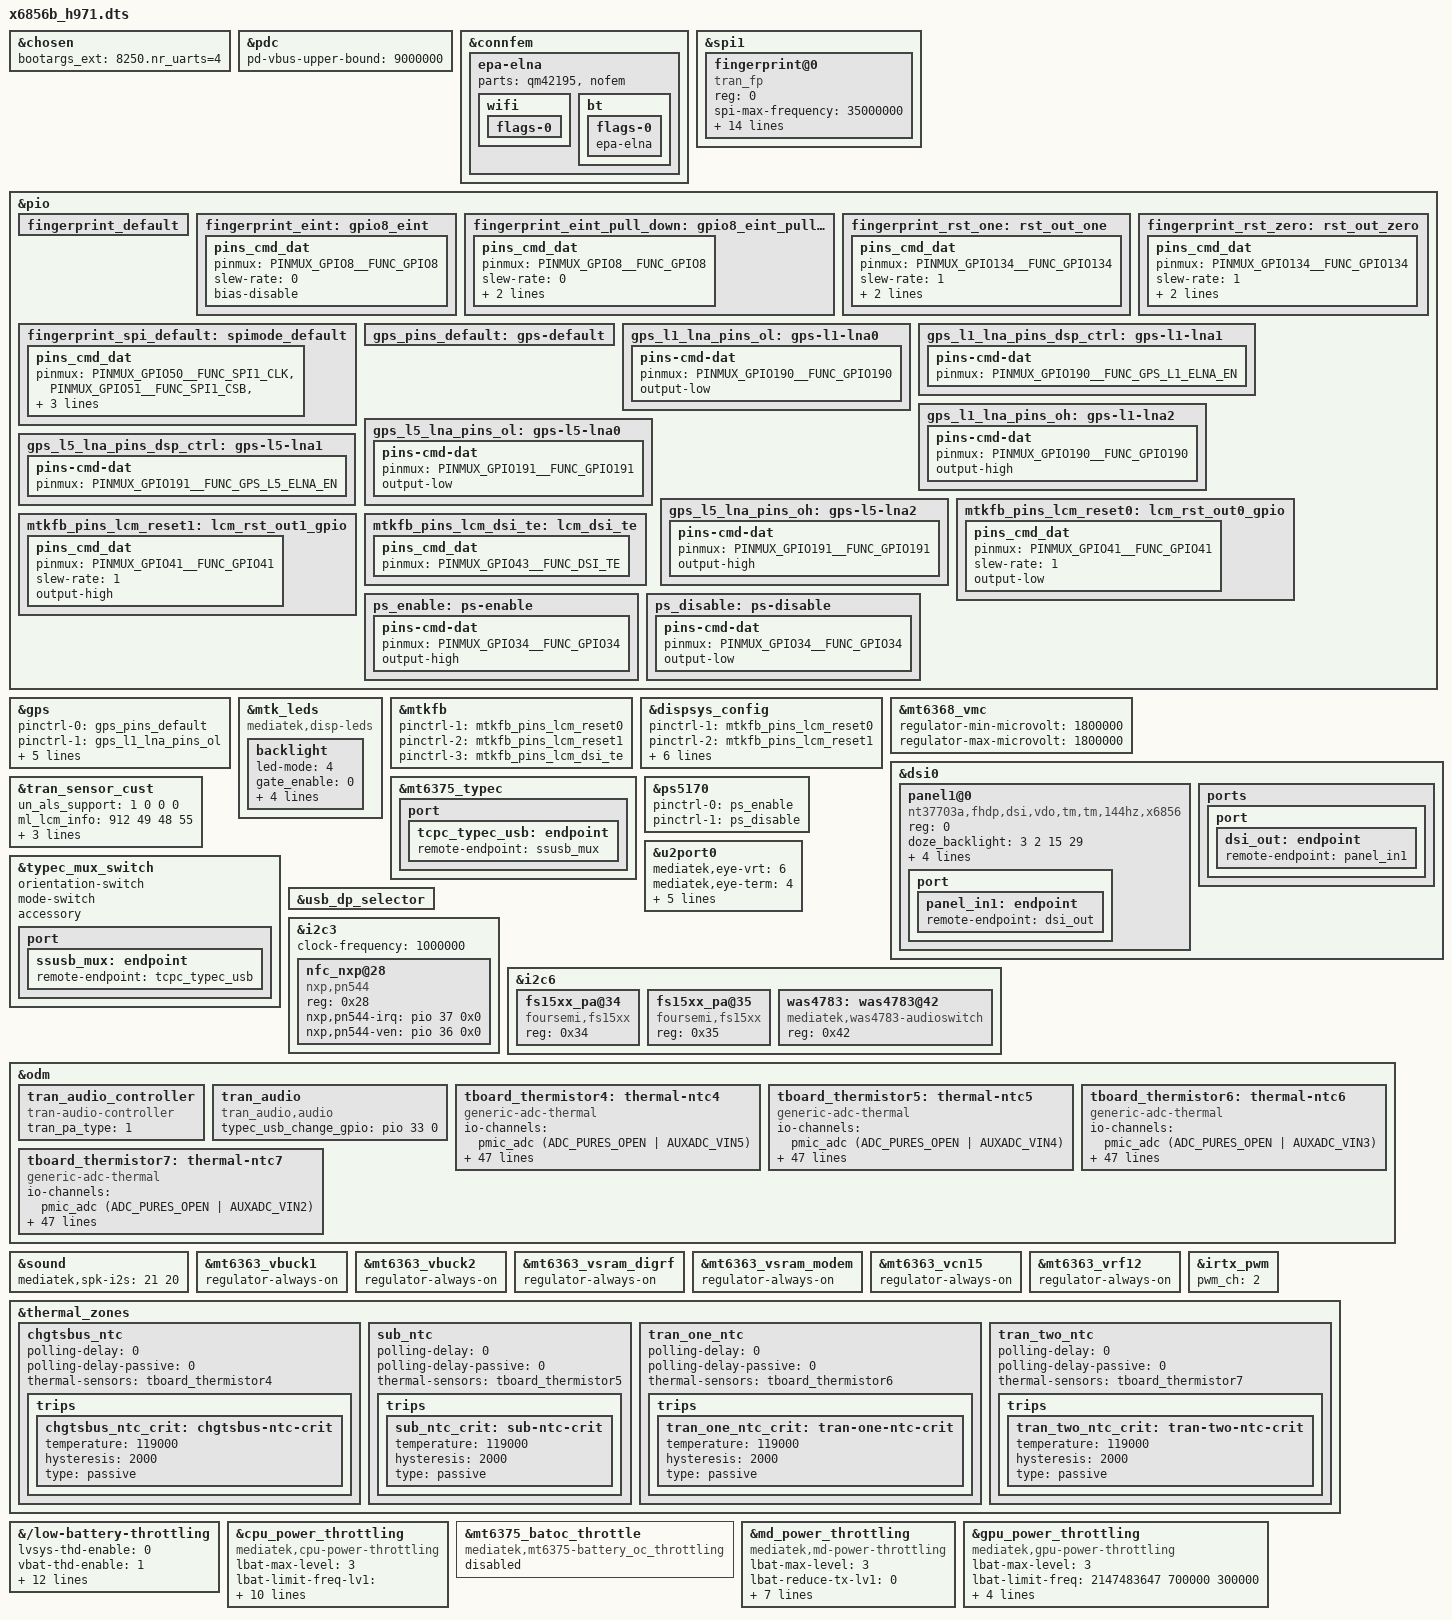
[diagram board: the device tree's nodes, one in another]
// SPDX-License-Identifier: (GPL-2.0 OR MIT)
/*
 * Copyright (C) 2022 MediaTek Inc.
 */
/dts-v1/;
/plugin/;
#include <dt-bindings/interrupt-controller/arm-gic.h>
#include <dt-bindings/interrupt-controller/irq.h>
#include <dt-bindings/pinctrl/mt6897-pinfunc.h>
#include <dt-bindings/phy/phy.h>
#include <dt-bindings/iio/mt635x-auxadc.h>
&chosen {
bootargs_ext = "8250.nr_uarts=4";
};

&pdc {
	pd-vbus-upper-bound = <9000000>;
};

&connfem {
/* Enable epa_elna node to support Wifi & BT ePA/eLNA FEM on customer load */
#if 1
	epa-elna {
		parts = <&qm42195 &nofem>;	/* [0] */
		wifi {
			flags-0 {
				/*open-loop;*/
			};
		};
		bt {
			flags-0 {
				/* choose one of: epa-elna/epa/elna/bypass */
				epa-elna;
			};
		};
	};
#endif
};

&spi1 {
	fingerprint@0 {
		compatible = "tran_fp";
		reg = <0>;
		spi-max-frequency = <35000000>;
		interrupt-parent = <&pio>;
		interrupts = <8 1 8 0>;
		debounce = <27 0>;
		irq-gpio = <8>;
		irq-gpio-std = <&pio 8 0x0>;
		reset-gpio = <134>;
		reset-gpio-std = <&pio 134 0x0>;
		vmch-supply = <&mt6368_vfp>;
		pinctrl-names ="tran_fp_default",
			"tran_fp_pin_irq",
			"tran_fp_irq_pull_down",
			"tran_fp_reset_high",
			"tran_fp_reset_low",
			"tran_fp_spi_default";
		pinctrl-0 = <&fingerprint_default>;
		pinctrl-1 = <&fingerprint_eint>;
		pinctrl-2 = <&fingerprint_eint_pull_down>;
		pinctrl-3 = <&fingerprint_rst_one>;
		pinctrl-4 = <&fingerprint_rst_zero>;
		pinctrl-5 = <&fingerprint_spi_default>;
		status = "okay";
	};
};
&pio {
fingerprint_default: fingerprint_default {
					};
fingerprint_eint: gpio8_eint {
					pins_cmd_dat {
						pinmux = <PINMUX_GPIO8__FUNC_GPIO8>;
						slew-rate = <0>;
						bias-disable;
					};
				};
fingerprint_eint_pull_down: gpio8_eint_pull_down {
								pins_cmd_dat {
									pinmux = <PINMUX_GPIO8__FUNC_GPIO8>;
									slew-rate = <0>;
									bias-pull-down = <00>;
									output-low;
								};
							};
fingerprint_rst_one: rst_out_one {
						pins_cmd_dat {
							pinmux = <PINMUX_GPIO134__FUNC_GPIO134>;
							slew-rate = <1>;
							bias-disable;
							output-high;
						};
					};
fingerprint_rst_zero: rst_out_zero {
						pins_cmd_dat {
							pinmux = <PINMUX_GPIO134__FUNC_GPIO134>;
							slew-rate = <1>;
							bias-disable;
							output-low;
						};
					};
fingerprint_spi_default: spimode_default {
							pins_cmd_dat {
								pinmux = <PINMUX_GPIO50__FUNC_SPI1_CLK>,
										<PINMUX_GPIO51__FUNC_SPI1_CSB>,
										<PINMUX_GPIO52__FUNC_SPI1_MI>,
										<PINMUX_GPIO53__FUNC_SPI1_MO>;
								drive-strength = <7>;
							};
						};
};

/* GPS GPIO standardization start */
&pio {
	gps_pins_default: gps-default {
	};
	gps_l1_lna_pins_ol: gps-l1-lna0 {
		pins-cmd-dat {
			pinmux = <PINMUX_GPIO190__FUNC_GPIO190>;
			output-low;
		};
	};
	gps_l1_lna_pins_dsp_ctrl: gps-l1-lna1 {
		pins-cmd-dat {
			pinmux = <PINMUX_GPIO190__FUNC_GPS_L1_ELNA_EN>;
		};
	};
	gps_l1_lna_pins_oh: gps-l1-lna2 {
		pins-cmd-dat {
			pinmux = <PINMUX_GPIO190__FUNC_GPIO190>;
			output-high;
		};
	};
	gps_l5_lna_pins_ol: gps-l5-lna0 {
		pins-cmd-dat {
			pinmux = <PINMUX_GPIO191__FUNC_GPIO191>;
			output-low;
		};
	};
	gps_l5_lna_pins_dsp_ctrl: gps-l5-lna1 {
		pins-cmd-dat {
			pinmux = <PINMUX_GPIO191__FUNC_GPS_L5_ELNA_EN>;
		};
	};
	gps_l5_lna_pins_oh: gps-l5-lna2 {
		pins-cmd-dat {
			pinmux = <PINMUX_GPIO191__FUNC_GPIO191>;
			output-high;
		};
	};
};
&gps {
	pinctrl-names = "default",
		"gps_l1_lna_disable",
		"gps_l1_lna_dsp_ctrl",
		"gps_l1_lna_enable",
		"gps_l5_lna_disable",
		"gps_l5_lna_dsp_ctrl",
		"gps_l5_lna_enable";
	pinctrl-0 = <&gps_pins_default>;
	pinctrl-1 = <&gps_l1_lna_pins_ol>;
	pinctrl-2 = <&gps_l1_lna_pins_dsp_ctrl>;
	pinctrl-3 = <&gps_l1_lna_pins_oh>;
	pinctrl-4 = <&gps_l5_lna_pins_ol>;
	pinctrl-5 = <&gps_l5_lna_pins_dsp_ctrl>;
	pinctrl-6 = <&gps_l5_lna_pins_oh>;
	status = "okay";
};
/* GPS GPIO standardization end */

&mtk_leds {
	compatible = "mediatek,disp-leds";

	backlight {
		led-mode = <4>;
		gate_enable = <0>;
		pwm_config = <0 1 0 0 0>;
		max-brightness = <511>;
		min-brightness = <0>;
		max-hw-brightness = <511>;
	};
};

&pio {
	mtkfb_pins_lcm_reset0: lcm_rst_out0_gpio {
		pins_cmd_dat {
			pinmux = <PINMUX_GPIO41__FUNC_GPIO41>;
			slew-rate = <1>;
			output-low;
		};
	};

	mtkfb_pins_lcm_reset1: lcm_rst_out1_gpio {
		pins_cmd_dat {
			pinmux = <PINMUX_GPIO41__FUNC_GPIO41>;
			slew-rate = <1>;
			output-high;
		};
	};

	mtkfb_pins_lcm_dsi_te: lcm_dsi_te {
		pins_cmd_dat {
			pinmux = <PINMUX_GPIO43__FUNC_DSI_TE>;
		};
	};
};

&mtkfb {
	pinctrl-names = "lcm_rst_out0_gpio", "lcm_rst_out1_gpio",
		"mode_te_te";
	pinctrl-1 = <&mtkfb_pins_lcm_reset0>;
	pinctrl-2 = <&mtkfb_pins_lcm_reset1>;
	pinctrl-3 = <&mtkfb_pins_lcm_dsi_te>;
	status = "okay";
};

&dispsys_config {
	pinctrl-names = "lcm_rst_out0_gpio", "lcm_rst_out1_gpio",
		"mode_te_te";
	pinctrl-1 = <&mtkfb_pins_lcm_reset0>;
	pinctrl-2 = <&mtkfb_pins_lcm_reset1>;
	pinctrl-3 = <&mtkfb_pins_lcm_dsi_te>;
	status = "okay";

	helper-value = <0>, /*MTK_DRM_OPT_STAGE*/
		<1>, /*MTK_DRM_OPT_USE_CMDQ*/
		<1>, /*MTK_DRM_OPT_USE_M4U*/
		<1>, /*MTK_DRM_OPT_MMQOS_SUPPORT*/
		<1>, /*MTK_DRM_OPT_MMDVFS_SUPPORT*/
		<0>, /*MTK_DRM_OPT_SODI_SUPPORT*/
		<1>, /*MTK_DRM_OPT_IDLE_MGR*/
		<0>, /*MTK_DRM_OPT_IDLEMGR_SWTCH_DECOUPLE*/
		<0>, /*MTK_DRM_OPT_IDLEMGR_BY_REPAINT*/
		<0>, /*MTK_DRM_OPT_IDLEMGR_ENTER_ULPS*/
		<0>, /*MTK_DRM_OPT_IDLEMGR_KEEP_LP11*/
		<0>, /*MTK_DRM_OPT_DYNAMIC_RDMA_GOLDEN_SETTING*/
		<1>, /*MTK_DRM_OPT_IDLEMGR_DISABLE_ROUTINE_IRQ*/
		<1>, /*MTK_DRM_OPT_IDLEMGR_ASYNC*/
		<0>, /*MTK_DRM_OPT_MET_LOG*/
		<1>, /*MTK_DRM_OPT_USE_PQ*/
		<1>, /*MTK_DRM_OPT_ESD_CHECK_RECOVERY*/
		<1>, /*MTK_DRM_OPT_ESD_CHECK_SWITCH*/
		<1>, /*MTK_DRM_OPT_PRESENT_FENCE*/
		<0>, /*MTK_DRM_OPT_RDMA_UNDERFLOW_AEE*/
		<1>, /*MTK_DRM_OPT_DSI_UNDERRUN_AEE*/
		<0>, /*MTK_DRM_OPT_ODDMR_OD_AEE*/
		<0>, /*MTK_DRM_OPT_ODDMR_DMR_AEE*/
		<1>, /*MTK_DRM_OPT_HRT*/
		<1>, /*MTK_DRM_OPT_HRT_MODE*/
		<0>, /*MTK_DRM_OPT_DELAYED_TRIGGER*/
		<1>, /*MTK_DRM_OPT_OVL_EXT_LAYER*/
		<1>, /*MTK_DRM_OPT_AOD*/
		<1>, /*MTK_DRM_OPT_RPO*/
		<0>, /*MTK_DRM_OPT_DUAL_PIPE*/
		<0>, /*MTK_DRM_OPT_DC_BY_HRT*/
		<1>, /*MTK_DRM_OPT_OVL_WCG*/
		<0>, /*MTK_DRM_OPT_OVL_SBCH*/
		<1>, /*MTK_DRM_OPT_COMMIT_NO_WAIT_VBLANK*/
		<0>, /*MTK_DRM_OPT_MET*/
		<0>, /*MTK_DRM_OPT_REG_PARSER_RAW_DUMP*/
		<0>, /*MTK_DRM_OPT_VP_PQ*/
		<0>, /*MTK_DRM_OPT_GAME_PQ*/
		<0>, /*MTK_DRM_OPT_MMPATH*/
		<1>, /*MTK_DRM_OPT_HBM*/
		<0>, /*MTK_DRM_OPT_VDS_PATH_SWITCH*/
		<0>, /*MTK_DRM_OPT_LAYER_REC*/
		<1>, /*MTK_DRM_OPT_CLEAR_LAYER*/
		<1>, /*MTK_DRM_OPT_LFR*/
		<0>, /*MTK_DRM_OPT_SF_PF*/
		<1>, /*MTK_DRM_OPT_DYN_MIPI_CHANGE*/
		<1>, /*MTK_DRM_OPT_PRIM_DUAL_PIPE*/
		<1>, /*MTK_DRM_OPT_MSYNC2_0*/
		<1>, /*MTK_DRM_OPT_MML_PRIMARY*/
		<1>, /*MTK_DRM_OPT_MML_SUPPORT_CMD_MODE*/
		<1>, /*MTK_DRM_OPT_MML_PQ*/
		<1>, /*MTK_DRM_OPT_MML_IR*/
		<0>, /*MTK_DRM_OPT_DUAL_TE*/
		<1>, /*MTK_DRM_OPT_RES_SWITCH*/
		<0>, /*MTK_DRM_OPT_PREFETCH_TE*/
		<0>, /*MTK_DRM_OPT_VIDLE_APSRC_OFF*/
		<0>, /*MTK_DRM_OPT_VIDLE_DSI_PLL_OFF*/
		<1>, /*MTK_DRM_OPT_CHECK_TRIGGER_MERGE*/
		<1>, /*MTK_DRM_OPT_VIRTUAL_DISP*/
		<1>, /*MTK_DRM_OPT_OVL_BW_MONITOR*/
		<0>, /*MTK_DRM_OPT_GPU_CACHE*/
		<1>, /*MTK_DRM_OPT_SPHRT*/
		<1>, /*MTK_DRM_OPT_SDPA_OVL_SWITCH*/
		<1>, /*MTK_DRM_OPT_HRT_BY_LARB*/
		<1>, /*MTK_DRM_OPT_RES_SWITCH_ON_AP*/
		<1>, /*MTK_DRM_OPT_TILE_OVERHEAD*/
		<0>; /*MTK_DRM_OPT_VBLANK_CONFIG_REC*/
};

&mt6368_vmc {
	regulator-min-microvolt = <1800000>;
	regulator-max-microvolt = <1800000>;
};

&dsi0 {
	status = "okay";
	#address-cells = <1>;
	#size-cells = <0>;
	panel1@0 {
		compatible = "nt37703a,fhdp,dsi,vdo,tm,tm,144hz,x6856";
		reg = <0>;
		doze_backlight = <3 2 15 29>;
		vddi-supply = <&mt6368_vmc>;
		dvdd-supply = <&ET5904LDO211>;
		vci-supply = <&mt6368_vmch>;
		reset-gpios = <&pio 41 0>;
		pinctrl-names = "default";
		port {
			panel_in1: endpoint {
				remote-endpoint = <&dsi_out>;
			};
		};
	};

	ports {
		port {
			dsi_out: endpoint {
				remote-endpoint = <&panel_in1>;
			};
		};
	};
};


&tran_sensor_cust {
    /*lcm info for sensor start*/
    /*als sensor support state*/
    un_als_support = <1 0 0 0>;/*ML MSL SL SSL*/
    /*main sensor:ML*/
    ml_lcm_info = <912 49 48 55>;/*offset_x, offset_y, clip_w, clip_h*/
    extra_ml_lcm_info = <920 75 27 25 80 20>; /*IC感光区起始坐标X IC感光区起始坐标Y IC宽 IC高  IC内占比 IC外占比*/
    /*main sub als lcm info:MSL*/
    /*lcm info for sensor end*/
    ml_nv_info = <1 1 1>; /*vendortype:SensorTek,  algotype:Cutout, version:V1_0_0*/
    nv_restore_time = <3>;
};


/* usb typec mux start */
&pio {

	ps_enable: ps-enable {
		pins-cmd-dat {
			pinmux = <PINMUX_GPIO34__FUNC_GPIO34>;
			output-high;
		};
	};

	ps_disable: ps-disable {
		pins-cmd-dat {
			pinmux = <PINMUX_GPIO34__FUNC_GPIO34>;
			output-low;
		};
	};

};

&mt6375_typec {
	//tcpc,en-fod;
	port {
		tcpc_typec_usb: endpoint {
			remote-endpoint = <&ssusb_mux>;
		};
	};
};

&typec_mux_switch {
	orientation-switch;
	mode-switch;
	accessory;
	port {
		ssusb_mux: endpoint {
			remote-endpoint = <&tcpc_typec_usb>;
		};
	};
};

&ps5170 {
	pinctrl-names = "enable", "disable";
	pinctrl-0 = <&ps_enable>;
	pinctrl-1 = <&ps_disable>;
	status = "okay";
};

&u2port0 {
        mediatek,eye-vrt = <6>;
        mediatek,eye-term = <4>;
        mediatek,rev6 = <2>;
                mediatek,discth = <9>;
        mediatek,eye-vrt-host = <6>;
        mediatek,eye-term-host = <4>;
        mediatek,rev6-host = <2>;
};

&usb_dp_selector {
	status = "okay";
};
/* usb typec mux end */

&i2c3 {
       clock-frequency = <1000000>;
       nfc_nxp@28 {
               compatible = "nxp,pn544";
               reg = <0x28>;
               nxp,pn544-irq = <&pio 37 0x0>;
               nxp,pn544-ven = <&pio 36 0x0>;
       };
};

&i2c6 {
       fs15xx_pa@34 {
               compatible = "foursemi,fs15xx";
               reg = <0x34>;
               status = "okay";
       };
       fs15xx_pa@35 {
               compatible = "foursemi,fs15xx";
               reg = <0x35>;
               status = "okay";
       };
	was4783: was4783@42 {
		status = "ok";
		compatible = "mediatek,was4783-audioswitch";
		reg = <0x42>;
	};
};
&odm {
	tran_audio_controller:tran_audio_controller {
		compatible = "tran-audio-controller";
		tran_pa_type = <1>;
	};
	tran_audio:tran_audio{
		compatible = "tran_audio,audio";
		typec_usb_change_gpio = <&pio 33 0>;
	};
	tboard_thermistor4: thermal-ntc4 {
		compatible = "generic-adc-thermal";
		#thermal-sensor-cells = <0>;
		io-channels = <&pmic_adc (ADC_PURES_OPEN | AUXADC_VIN5)>;
		io-channel-names = "sensor-channel";
		temperature-lookup-table =
            <(-40000) 1799>,
			<(-39000) 1796>,
			<(-38000) 1792>,
			<(-37000) 1789>,
			<(-36000) 1786>,
			<(-35000) 1782>,
			<(-34000) 1778>,
			<(-33000) 1774>,
			<(-32000) 1769>,
			<(-31000) 1764>,
			<(-30000) 1759>,
			<(-29000) 1754>,
			<(-28000) 1749>,
			<(-27000) 1743>,
			<(-26000) 1737>,
			<(-25000) 1730>,
			<(-24000) 1723>,
			<(-23000) 1716>,
			<(-22000) 1709>,
			<(-21000) 1701>,
			<(-20000) 1692>,
			<(-19000) 1684>,
			<(-18000) 1675>,
			<(-17000) 1665>,
			<(-16000) 1655>,
			<(-15000) 1645>,
			<(-14000) 1634>,
			<(-13000) 1623>,
			<(-12000) 1612>,
			<(-11000) 1600>,
			<(-10000) 1587>,
			<(-9000) 1574>,
			<(-8000) 1561>,
			<(-7000) 1547>,
			<(-6000) 1532>,
			<(-5000) 1518>,
			<(-4000) 1502>,
			<(-3000) 1487>,
			<(-2000) 1471>,
			<(-1000) 1454>,
			<0 1437>,
			<1000 1419>,
			<2000 1402>,
			<3000 1383>,
			<4000 1365>,
			<5000 1346>,
			<6000 1326>,
			<7000 1306>,
			<8000 1286>,
			<9000 1266>,
			<10000 1245>,
			<11000 1225>,
			<12000 1203>,
			<13000 1182>,
			<14000 1161>,
			<15000 1139>,
			<16000 1117>,
			<17000 1095>,
			<18000 1073>,
			<19000 1051>,
			<20000 1029>,
			<21000 1007>,
			<22000 985>,
			<23000 963>,
			<24000 941>,
			<25000 920>,
			<26000 898>,
			<27000 876>,
			<28000 855>,
			<29000 834>,
			<30000 813>,
			<31000 792>,
			<32000 772>,
			<33000 751>,
			<34000 731>,
			<35000 712>,
			<36000 692>,
			<37000 673>,
			<38000 655>,
			<39000 636>,
			<40000 618>,
			<41000 601>,
			<42000 583>,
			<43000 566>,
			<44000 550>,
			<45000 534>,
			<46000 518>,
			<47000 502>,
			<48000 487>,
			<49000 472>,
			<50000 458>,
			<51000 444>,
			<52000 430>,
			<53000 417>,
			<54000 404>,
			<55000 392>,
			<56000 380>,
			<57000 368>,
			<58000 356>,
			<59000 345>,
			<60000 334>,
			<61000 324>,
			<62000 313>,
			<63000 303>,
			<64000 294>,
			<65000 284>,
			<66000 275>,
			<67000 267>,
			<68000 258>,
			<69000 250>,
			<70000 242>,
			<71000 234>,
			<72000 227>,
			<73000 220>,
			<74000 213>,
			<75000 206>,
			<76000 199>,
			<77000 193>,
			<78000 187>,
			<79000 181>,
			<80000 175>,
			<81000 170>,
			<82000 164>,
			<83000 159>,
			<84000 154>,
			<85000 149>,
			<86000 145>,
			<87000 140>,
			<88000 136>,
			<89000 132>,
			<90000 128>,
			<91000 124>,
			<92000 120>,
			<93000 116>,
			<94000 113>,
			<95000 109>,
			<96000 106>,
			<97000 103>,
			<98000 99>,
			<99000 96>,
			<100000 94>,
			<101000 91>,
			<102000 88>,
			<103000 85>,
			<104000 83>,
			<105000 80>,
			<106000 78>,
			<107000 76>,
			<108000 73>,
			<109000 71>,
			<110000 69>,
			<111000 67>,
			<112000 65>,
			<113000 63>,
			<114000 61>,
			<115000 60>,
			<116000 58>,
			<117000 56>,
			<118000 55>,
			<119000 53>,
			<120000 52>,
			<121000 50>,
			<122000 49>,
			<123000 47>,
			<124000 46>,
			<125000 45>;
	};

	tboard_thermistor5: thermal-ntc5 {
		compatible = "generic-adc-thermal";
		#thermal-sensor-cells = <0>;
		io-channels = <&pmic_adc (ADC_PURES_OPEN | AUXADC_VIN4)>;
		io-channel-names = "sensor-channel";
		temperature-lookup-table =
            <(-40000) 1799>,
			<(-39000) 1796>,
			<(-38000) 1792>,
			<(-37000) 1789>,
			<(-36000) 1786>,
			<(-35000) 1782>,
			<(-34000) 1778>,
			<(-33000) 1774>,
			<(-32000) 1769>,
			<(-31000) 1764>,
			<(-30000) 1759>,
			<(-29000) 1754>,
			<(-28000) 1749>,
			<(-27000) 1743>,
			<(-26000) 1737>,
			<(-25000) 1730>,
			<(-24000) 1723>,
			<(-23000) 1716>,
			<(-22000) 1709>,
			<(-21000) 1701>,
			<(-20000) 1692>,
			<(-19000) 1684>,
			<(-18000) 1675>,
			<(-17000) 1665>,
			<(-16000) 1655>,
			<(-15000) 1645>,
			<(-14000) 1634>,
			<(-13000) 1623>,
			<(-12000) 1612>,
			<(-11000) 1600>,
			<(-10000) 1587>,
			<(-9000) 1574>,
			<(-8000) 1561>,
			<(-7000) 1547>,
			<(-6000) 1532>,
			<(-5000) 1518>,
			<(-4000) 1502>,
			<(-3000) 1487>,
			<(-2000) 1471>,
			<(-1000) 1454>,
			<0 1437>,
			<1000 1419>,
			<2000 1402>,
			<3000 1383>,
			<4000 1365>,
			<5000 1346>,
			<6000 1326>,
			<7000 1306>,
			<8000 1286>,
			<9000 1266>,
			<10000 1245>,
			<11000 1225>,
			<12000 1203>,
			<13000 1182>,
			<14000 1161>,
			<15000 1139>,
			<16000 1117>,
			<17000 1095>,
			<18000 1073>,
			<19000 1051>,
			<20000 1029>,
			<21000 1007>,
			<22000 985>,
			<23000 963>,
			<24000 941>,
			<25000 920>,
			<26000 898>,
			<27000 876>,
			<28000 855>,
			<29000 834>,
			<30000 813>,
			<31000 792>,
			<32000 772>,
			<33000 751>,
			<34000 731>,
			<35000 712>,
			<36000 692>,
			<37000 673>,
			<38000 655>,
			<39000 636>,
			<40000 618>,
			<41000 601>,
			<42000 583>,
			<43000 566>,
			<44000 550>,
			<45000 534>,
			<46000 518>,
			<47000 502>,
			<48000 487>,
			<49000 472>,
			<50000 458>,
			<51000 444>,
			<52000 430>,
			<53000 417>,
			<54000 404>,
			<55000 392>,
			<56000 380>,
			<57000 368>,
			<58000 356>,
			<59000 345>,
			<60000 334>,
			<61000 324>,
			<62000 313>,
			<63000 303>,
			<64000 294>,
			<65000 284>,
			<66000 275>,
			<67000 267>,
			<68000 258>,
			<69000 250>,
			<70000 242>,
			<71000 234>,
			<72000 227>,
			<73000 220>,
			<74000 213>,
			<75000 206>,
			<76000 199>,
			<77000 193>,
			<78000 187>,
			<79000 181>,
			<80000 175>,
			<81000 170>,
			<82000 164>,
			<83000 159>,
			<84000 154>,
			<85000 149>,
			<86000 145>,
			<87000 140>,
			<88000 136>,
			<89000 132>,
			<90000 128>,
			<91000 124>,
			<92000 120>,
			<93000 116>,
			<94000 113>,
			<95000 109>,
			<96000 106>,
			<97000 103>,
			<98000 99>,
			<99000 96>,
			<100000 94>,
			<101000 91>,
			<102000 88>,
			<103000 85>,
			<104000 83>,
			<105000 80>,
			<106000 78>,
			<107000 76>,
			<108000 73>,
			<109000 71>,
			<110000 69>,
			<111000 67>,
			<112000 65>,
			<113000 63>,
			<114000 61>,
			<115000 60>,
			<116000 58>,
			<117000 56>,
			<118000 55>,
			<119000 53>,
			<120000 52>,
			<121000 50>,
			<122000 49>,
			<123000 47>,
			<124000 46>,
			<125000 45>;
	};

	tboard_thermistor6: thermal-ntc6 {
		compatible = "generic-adc-thermal";
		#thermal-sensor-cells = <0>;
		io-channels = <&pmic_adc (ADC_PURES_OPEN | AUXADC_VIN3)>;
		io-channel-names = "sensor-channel";
		temperature-lookup-table =
            <(-40000) 1799>,
			<(-39000) 1796>,
			<(-38000) 1792>,
			<(-37000) 1789>,
			<(-36000) 1786>,
			<(-35000) 1782>,
			<(-34000) 1778>,
			<(-33000) 1774>,
			<(-32000) 1769>,
			<(-31000) 1764>,
			<(-30000) 1759>,
			<(-29000) 1754>,
			<(-28000) 1749>,
			<(-27000) 1743>,
			<(-26000) 1737>,
			<(-25000) 1730>,
			<(-24000) 1723>,
			<(-23000) 1716>,
			<(-22000) 1709>,
			<(-21000) 1701>,
			<(-20000) 1692>,
			<(-19000) 1684>,
			<(-18000) 1675>,
			<(-17000) 1665>,
			<(-16000) 1655>,
			<(-15000) 1645>,
			<(-14000) 1634>,
			<(-13000) 1623>,
			<(-12000) 1612>,
			<(-11000) 1600>,
			<(-10000) 1587>,
			<(-9000) 1574>,
			<(-8000) 1561>,
			<(-7000) 1547>,
			<(-6000) 1532>,
			<(-5000) 1518>,
			<(-4000) 1502>,
			<(-3000) 1487>,
			<(-2000) 1471>,
			<(-1000) 1454>,
			<0 1437>,
			<1000 1419>,
			<2000 1402>,
			<3000 1383>,
			<4000 1365>,
			<5000 1346>,
			<6000 1326>,
			<7000 1306>,
			<8000 1286>,
			<9000 1266>,
			<10000 1245>,
			<11000 1225>,
			<12000 1203>,
			<13000 1182>,
			<14000 1161>,
			<15000 1139>,
			<16000 1117>,
			<17000 1095>,
			<18000 1073>,
			<19000 1051>,
			<20000 1029>,
			<21000 1007>,
			<22000 985>,
			<23000 963>,
			<24000 941>,
			<25000 920>,
			<26000 898>,
			<27000 876>,
			<28000 855>,
			<29000 834>,
			<30000 813>,
			<31000 792>,
			<32000 772>,
			<33000 751>,
			<34000 731>,
			<35000 712>,
			<36000 692>,
			<37000 673>,
			<38000 655>,
			<39000 636>,
			<40000 618>,
			<41000 601>,
			<42000 583>,
			<43000 566>,
			<44000 550>,
			<45000 534>,
			<46000 518>,
			<47000 502>,
			<48000 487>,
			<49000 472>,
			<50000 458>,
			<51000 444>,
			<52000 430>,
			<53000 417>,
			<54000 404>,
			<55000 392>,
			<56000 380>,
			<57000 368>,
			<58000 356>,
			<59000 345>,
			<60000 334>,
			<61000 324>,
			<62000 313>,
			<63000 303>,
			<64000 294>,
			<65000 284>,
			<66000 275>,
			<67000 267>,
			<68000 258>,
			<69000 250>,
			<70000 242>,
			<71000 234>,
			<72000 227>,
			<73000 220>,
			<74000 213>,
			<75000 206>,
			<76000 199>,
			<77000 193>,
			<78000 187>,
			<79000 181>,
			<80000 175>,
			<81000 170>,
			<82000 164>,
			<83000 159>,
			<84000 154>,
			<85000 149>,
			<86000 145>,
			<87000 140>,
			<88000 136>,
			<89000 132>,
			<90000 128>,
			<91000 124>,
			<92000 120>,
			<93000 116>,
			<94000 113>,
			<95000 109>,
			<96000 106>,
			<97000 103>,
			<98000 99>,
			<99000 96>,
			<100000 94>,
			<101000 91>,
			<102000 88>,
			<103000 85>,
			<104000 83>,
			<105000 80>,
			<106000 78>,
			<107000 76>,
			<108000 73>,
			<109000 71>,
			<110000 69>,
			<111000 67>,
			<112000 65>,
			<113000 63>,
			<114000 61>,
			<115000 60>,
			<116000 58>,
			<117000 56>,
			<118000 55>,
			<119000 53>,
			<120000 52>,
			<121000 50>,
			<122000 49>,
			<123000 47>,
			<124000 46>,
			<125000 45>;
	};

	tboard_thermistor7: thermal-ntc7 {
		compatible = "generic-adc-thermal";
		#thermal-sensor-cells = <0>;
		io-channels = <&pmic_adc (ADC_PURES_OPEN | AUXADC_VIN2)>;
		io-channel-names = "sensor-channel";
		temperature-lookup-table =
            <(-40000) 1799>,
			<(-39000) 1796>,
			<(-38000) 1792>,
			<(-37000) 1789>,
			<(-36000) 1786>,
			<(-35000) 1782>,
			<(-34000) 1778>,
			<(-33000) 1774>,
			<(-32000) 1769>,
			<(-31000) 1764>,
			<(-30000) 1759>,
			<(-29000) 1754>,
			<(-28000) 1749>,
			<(-27000) 1743>,
			<(-26000) 1737>,
			<(-25000) 1730>,
			<(-24000) 1723>,
			<(-23000) 1716>,
			<(-22000) 1709>,
			<(-21000) 1701>,
			<(-20000) 1692>,
			<(-19000) 1684>,
			<(-18000) 1675>,
			<(-17000) 1665>,
			<(-16000) 1655>,
			<(-15000) 1645>,
			<(-14000) 1634>,
			<(-13000) 1623>,
			<(-12000) 1612>,
			<(-11000) 1600>,
			<(-10000) 1587>,
			<(-9000) 1574>,
			<(-8000) 1561>,
			<(-7000) 1547>,
			<(-6000) 1532>,
			<(-5000) 1518>,
			<(-4000) 1502>,
			<(-3000) 1487>,
			<(-2000) 1471>,
			<(-1000) 1454>,
			<0 1437>,
			<1000 1419>,
			<2000 1402>,
			<3000 1383>,
			<4000 1365>,
			<5000 1346>,
			<6000 1326>,
			<7000 1306>,
			<8000 1286>,
			<9000 1266>,
			<10000 1245>,
			<11000 1225>,
			<12000 1203>,
			<13000 1182>,
			<14000 1161>,
			<15000 1139>,
			<16000 1117>,
			<17000 1095>,
			<18000 1073>,
			<19000 1051>,
			<20000 1029>,
			<21000 1007>,
			<22000 985>,
			<23000 963>,
			<24000 941>,
			<25000 920>,
			<26000 898>,
			<27000 876>,
			<28000 855>,
			<29000 834>,
			<30000 813>,
			<31000 792>,
			<32000 772>,
			<33000 751>,
			<34000 731>,
			<35000 712>,
			<36000 692>,
			<37000 673>,
			<38000 655>,
			<39000 636>,
			<40000 618>,
			<41000 601>,
			<42000 583>,
			<43000 566>,
			<44000 550>,
			<45000 534>,
			<46000 518>,
			<47000 502>,
			<48000 487>,
			<49000 472>,
			<50000 458>,
			<51000 444>,
			<52000 430>,
			<53000 417>,
			<54000 404>,
			<55000 392>,
			<56000 380>,
			<57000 368>,
			<58000 356>,
			<59000 345>,
			<60000 334>,
			<61000 324>,
			<62000 313>,
			<63000 303>,
			<64000 294>,
			<65000 284>,
			<66000 275>,
			<67000 267>,
			<68000 258>,
			<69000 250>,
			<70000 242>,
			<71000 234>,
			<72000 227>,
			<73000 220>,
			<74000 213>,
			<75000 206>,
			<76000 199>,
			<77000 193>,
			<78000 187>,
			<79000 181>,
			<80000 175>,
			<81000 170>,
			<82000 164>,
			<83000 159>,
			<84000 154>,
			<85000 149>,
			<86000 145>,
			<87000 140>,
			<88000 136>,
			<89000 132>,
			<90000 128>,
			<91000 124>,
			<92000 120>,
			<93000 116>,
			<94000 113>,
			<95000 109>,
			<96000 106>,
			<97000 103>,
			<98000 99>,
			<99000 96>,
			<100000 94>,
			<101000 91>,
			<102000 88>,
			<103000 85>,
			<104000 83>,
			<105000 80>,
			<106000 78>,
			<107000 76>,
			<108000 73>,
			<109000 71>,
			<110000 69>,
			<111000 67>,
			<112000 65>,
			<113000 63>,
			<114000 61>,
			<115000 60>,
			<116000 58>,
			<117000 56>,
			<118000 55>,
			<119000 53>,
			<120000 52>,
			<121000 50>,
			<122000 49>,
			<123000 47>,
			<124000 46>,
			<125000 45>;
	};
};

&sound {
	mediatek,spk-i2s = <21 20>;
};

&mt6363_vbuck1 {
	regulator-always-on;
};

&mt6363_vbuck2 {
	regulator-always-on;
};

&mt6363_vsram_digrf {
	regulator-always-on;
};

&mt6363_vsram_modem {
	regulator-always-on;
};

&mt6363_vcn15 {
	regulator-always-on;
};

&mt6363_vrf12 {
	regulator-always-on;
};

&irtx_pwm {
	pwm_ch = <2>;
	status = "okay";
};

&thermal_zones {
    chgtsbus_ntc: chgtsbus_ntc {
		polling-delay = <0>; /* milliseconds */
		polling-delay-passive = <0>; /* milliseconds */
		thermal-sensors = <&tboard_thermistor4>;

		trips {
			chgtsbus_ntc_crit: chgtsbus-ntc-crit {
				temperature = <119000>;
				hysteresis = <2000>;
				type = "passive";
			};
		};
	};
	sub_ntc: sub_ntc {
		polling-delay = <0>; /* milliseconds */
		polling-delay-passive = <0>; /* milliseconds */
		thermal-sensors = <&tboard_thermistor5>;

		trips {
			sub_ntc_crit: sub-ntc-crit {
				temperature = <119000>;
				hysteresis = <2000>;
				type = "passive";
			};
		};
	};
	tran_one_ntc: tran_one_ntc {
		polling-delay = <0>; /* milliseconds */
		polling-delay-passive = <0>; /* milliseconds */
		thermal-sensors = <&tboard_thermistor6>;

		trips {
			tran_one_ntc_crit: tran-one-ntc-crit {
				temperature = <119000>;
				hysteresis = <2000>;
				type = "passive";
			};
		};
	};
	tran_two_ntc: tran_two_ntc {
		polling-delay = <0>; /* milliseconds */
		polling-delay-passive = <0>; /* milliseconds */
		thermal-sensors = <&tboard_thermistor7>;

		trips {
			tran_two_ntc_crit: tran-two-ntc-crit {
				temperature = <119000>;
				hysteresis = <2000>;
				type = "passive";
			};
		};
	};
};
&{/low-battery-throttling} {
	lvsys-thd-enable = <0>;
	vbat-thd-enable = <1>;
	thd-volts-l = <
		3500 3200 2700
		3700 3500 2800
		4000 3700 3300
		4150 4100 3700>;
	thd-volts-h = <
		3600 3500 3200
		3800 3700 3500
		4200 4000 3700
		4400 4150 4100>;
	thd-volts-l-2s = <
		3500 3200 2700
		3700 3500 2800
		4000 3700 3300
		4150 4100 3700>;
	thd-volts-h-2s = <
		3600 3500 3200
		3800 3700 3500
		4200 4000 3700
		4400 4150 4100>;
	lvsys-thd-volt-l = <2900>;
	lvsys-thd-volt-h = <3100>;
	temperature-max-stage = <3>;
	temperature-stage-threshold = <11 0 (-10)>;
};
&cpu_power_throttling {
	compatible = "mediatek,cpu-power-throttling";
	lbat-max-level = <3>;
	lbat-limit-freq-lv1 = < 2147483647  2147483647 2147483647>;
	lbat-limit-freq-lv2 = < 1200000  1700000 1800000>;
	lbat-limit-freq-lv3 = < 900000  900000 900000>;
	oc-max-level = <2>;
	oc-limit-freq-lv1 = < 2147483647  2147483647 2147483647>;
	oc-limit-freq-lv2 = < 900000  900000 900000>;
	soc-max-level = <1>;
	soc-limit-freq-lv1 = < 2147483647  2147483647 2147483647>;
};
&mt6375_batoc_throttle {
	compatible = "mediatek,mt6375-battery_oc_throttling";
	status = "disabled";
};
&md_power_throttling {
	compatible = "mediatek,md-power-throttling";

	lbat-max-level = <3>;
	lbat-reduce-tx-lv1 = <0>;
	lbat-reduce-tx-lv2 = <0>;
	lbat-reduce-tx-lv3 = <0>;

	oc-max-level = <2>;
	oc-reduce-tx-lv1 = <0>;
	oc-reduce-tx-lv2 = <0>;

	soc-max-level = <1>;
	soc-reduce-tx-lv1 = <0>;
};
&gpu_power_throttling {
	compatible = "mediatek,gpu-power-throttling";

	lbat-max-level = <3>;
	lbat-limit-freq = <2147483647 700000 300000>;

	oc-max-level = <2>;
	oc-limit-freq = <1200000 700000>;

	soc-max-level = <1>;
	soc-limit-freq = <2147483647>;
};
#include "mediatek/cust_k6897_connfem.dtsi"
#include "mediatek/tc_led.dtsi"
#include "mediatek/led/x6856b_h971/tran_led_aw20144_x6856.dtsi"
#include "mediatek/touch/x6856b_h971/tran_mt6897_touch_x6856b.dtsi"
#include "mediatek/msdc/x6856b_h971/cust_mt6897_msdc.dtsi"
#include "mediatek/camera/x6856b/cust_mt6897_camera_v4l2.dtsi"
#include "mediatek/charge/x6856b_h971/mt5728.dtsi"
#include "mediatek/charge/x6856b_h971/rt6160.dtsi"
#include "mediatek/charge/x6856b_h971/boost_hl7603.dtsi"
#include "mediatek/charge/x6856b_h971/tc_sc8565.dtsi"
#include "mediatek/charge/x6856b_h971/fuel_gauge.dtsi"
#include "mediatek/charge/x6856b_h971/master_476584_FG1000A_REV03_S_ad.dtsi"
#include "mediatek/charge/x6856b_h971/tran_usb_ctrl.dtsi"
#include "mediatek/charge/x6856b_h971/tc_pe50.dtsi"
#include "mediatek/charge/x6856b_h971/protocol_ta.dtsi"
#include "mediatek/charge/x6856b_h971/tc_charger.dtsi"
#include "mediatek/charge/x6856b_h971/tc_charger_lk.dtsi"
#include "mediatek/charge/x6856b_h971/bat_setting/mt6897_battery_prop.dtsi"
#include <x6856b_h971/cust.dtsi>
#include "sensor/tran_mt6881_x6856b_h971_sensor.dtsi"
/*End of this file, DO NOT ADD ANYTHING HERE*/
